# MM32L3xx register map
Vendor: MindMotion Ltd.; Series: MM32L3; File version: 1.4
CPU: CM3 r1p1, little endian, no MPU, no FPU, 4 interrupt priority bits
Registers are 32-bit, read-write, reset 0x0 unless marked. A register's access mark holds for its fields unless they carry their own. Offsets are from the block's base; [hi:lo] are bit positions.

## I2C1 — Inter integrated circuit
Base 0x40005400
Same registers: I2C2 0x40005800
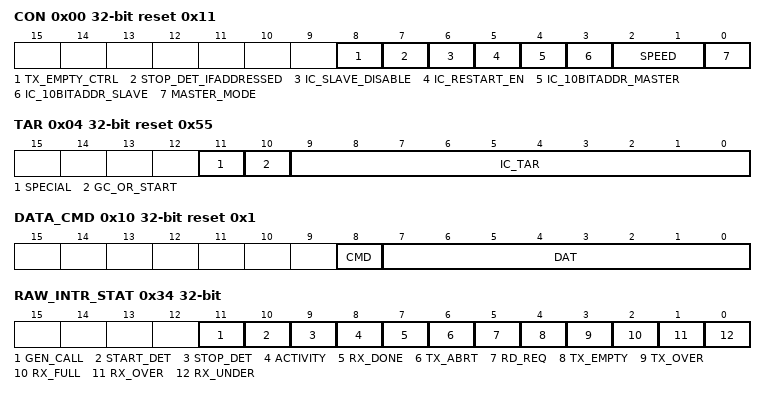
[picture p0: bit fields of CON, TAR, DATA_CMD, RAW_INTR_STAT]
0x00 CON reset 0x11
  [8] TX_EMPTY_CTRL — This bit controls the generation of the TX_EMPTY interrupt
  [7] STOP_DET_IFADDRESSED
  [6] IC_SLAVE_DISABLE — This bit controls whether I2C has its slave diabled
  [5] IC_RESTART_EN — Determines whether RESTART comdtions may be sent when acting as a master
  [4] IC_10BITADDR_MASTER — Address mode when acting as a master
  [3] IC_10BITADDR_SLAVE — When acting as a alsve
  [2:1] SPEED — These bits control at which speed the DW_apb_i2c operates
  [0] MASTER_MODE — This bit controls whether the DW_apb_i2c master is enabled
0x04 TAR reset 0x55
  [11] SPECIAL — This bit indicates whether software performs a General Call or START BYTE conmmend
  [10] GC_OR_START — If bit 11(SPECIAL)is set to 1
  [9:0] IC_TAR — This is the target address for any master transaction
0x08 SAR reset 0x55
  [9:0] IC_SAR — The IC_SAR holds the slave address when the i2c is operation as a slave
0x0C HS_MADDR reset 0x1
  [2:0] IC_HS_MAR — This bit field holds the value of the I2C HS mode master mode
0x10 DATA_CMD reset 0x1
  [8] CMD — This bit controls whether a read or a write is perormed
  [7:0] DAT — This register contains the data to be transimitted or received on the i2c bus.
0x14 SS_SCL_HCNT reset 0x190
  [15:0] IC_SS_SCL_HCNT — This register sets the SCL clock high period count for standard speed
0x18 SS_SCL_LCNT reset 0x1D6
  [15:0] IC_SS_SCL_LCNT — This register sets the SCL clock low period count for standard speed
0x1C FS_SCL_HCNT reset 0x36
  [15:0] IC_FS_SCL_HCNT — This register sets the SCL clock high_period count for standard speed
0x20 FS_SCL_LCNT reset 0x82
  [15:0] IC_FS_SCL_LCNT — This register sets the SCL clock low period count for standard speed
0x24 HS_SCL_HCNT reset 0x6
  [15:0] IC_HS_SCL_HCNT — This register sets the SCL clock high_period count for standard speed
0x28 HS_SCL_LCNT reset 0x10
  [15:0] IC_HS_SCL_LCNT — This register sets the SCL clock low period count for standard speed
0x2C INTR_STAT ro
  [15:0] IC_RAW_INTR_STAT
0x30 INTR_MASK
0x34 RAW_INTR_STAT ro
  [11] GEN_CALL — General call
  [10] START_DET — Start condition detection
  [9] STOP_DET — Stop condition detection
  [8] ACTIVITY — This bit captures DW_spb_i2c acticity and stays set until it is cleared
  [7] RX_DONE — Transmit done
  [6] TX_ABRT — Transmit abort
  [5] RD_REQ — Read request
  [4] TX_EMPTY — Transmit buffer empty
  [3] TX_OVER — Transmit buffer over
  [2] RX_FULL — Receive buffer not empty
  [1] RX_OVER — Receive buffer over
  [0] RX_UNDER — Receive buffer under
0x38 RX_TL ro
  [7:0] RX_TL — Receive FIFO threshold level
0x3C TX_TL ro
  [7:0] TX_TL — Transmit FIFO threshold level
0x40 CLR_INTR ro
  [0] CLR_INTR — Read this register to clear the combined interrupt
0x44 CLR_RX_UNDER ro
  [0] CLR_RX_UNDER — Read this register to clear the RX_UNDER interrupt(bit 0)of the IC_RAW_INTR_STAT register
0x48 CLR_RX_OVER ro
  [0] CLR_RX_OVER — Read this register to clear the RX_UNDER interrupt(bit 1)of the IC_RAW_INTR_STAT register
0x4C CLR_TX_OVER ro
  [0] CLR_TX_OVER — Read this register to clear the RX_UNDER interrupt(bit 3)of the IC_RAW_INTR_STAT register
0x50 CLR_RD_REQ ro
  [0] CLR_RD_REQ — Read this register to clear the RX_UNDER interrupt(bit 5)of the IC_RAW_INTR_STAT register
0x54 CLR_TX_ABRT ro
  [0] CLR_TX_ABRT — Read this register to clear the RX_UNDER interrupt(bit 6)of the IC_RAW_INTR_STAT register
0x58 CLR_RX_DONE ro
  [0] CLR_RX_DONE — Read this register to clear the RX_UNDER interrupt(bit 7)of the IC_RAW_INTR_STAT register
0x5C CLR_ACTIVITY ro
  [0] CLR_ACTIVITY — Reading this register clears the ACTIVITY interrupt if the I2C is not active anymore
0x60 CLR_STOP_DET ro
  [0] CLR_STOP_DET — Read this register to clear the STOP_DET interrupt(bit 9)of the IC_RAW_INTR_STAT register
0x64 CLR_START_DET ro
  [0] CLR_START_DET — Read this register to clear the START_DET interrupt(bit 10)of the IC_RAW_INTR_STAT register
0x68 CLR_GEN_CALL ro
  [0] CLR_GEN_CALL — Read this register to clear the GEN_CALL interrupt(bit 11)of the IC_RAW_INTR_STAT register
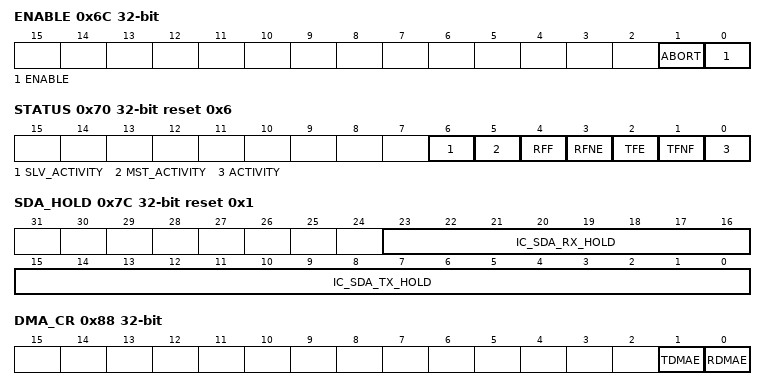
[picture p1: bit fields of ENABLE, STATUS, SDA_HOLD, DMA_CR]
0x6C ENABLE
  [1] ABORT — I2C transfer abort
  [0] ENABLE — I2C mode enable
0x70 STATUS ro reset 0x6
  [6] SLV_ACTIVITY — Slave FSM activity status
  [5] MST_ACTIVITY — Master FSM activity status
  [4] RFF — Receive FIFO completely full
  [3] RFNE — Receive FIFO not empty
  [2] TFE — Transmit FIFO completely empty
  [1] TFNF — Transmit FIFO not full
  [0] ACTIVITY — I2C activity status
0x74 TXFLR ro reset 0x6
  [1:0] TXFLR — Transmit FIFO level.Contains the number of valid data entires in the transmit FIFO
0x78 RXFLR ro reset 0x6
  [1:0] RXFLR — Receive FIFO level. Contains the number of valid data entires in the receive FIFO
0x7C SDA_HOLD ro reset 0x1
  [23:16] IC_SDA_RX_HOLD — Sets the required SDA hold time in units of ic_clk period
  [15:0] IC_SDA_TX_HOLD — Sets the required SDA hold time in units of ic_clk period
0x88 DMA_CR
  [1] TDMAE — Transmit DMA enable
  [0] RDMAE — Receive DMA enable
0x94 SDA_SETUP reset 0x64
  [7:0] SDA_SETUP
0x98 ACK_GENERAL_CALL reset 0x1
  [0] ACK_GEN_CALL — ACK general call
